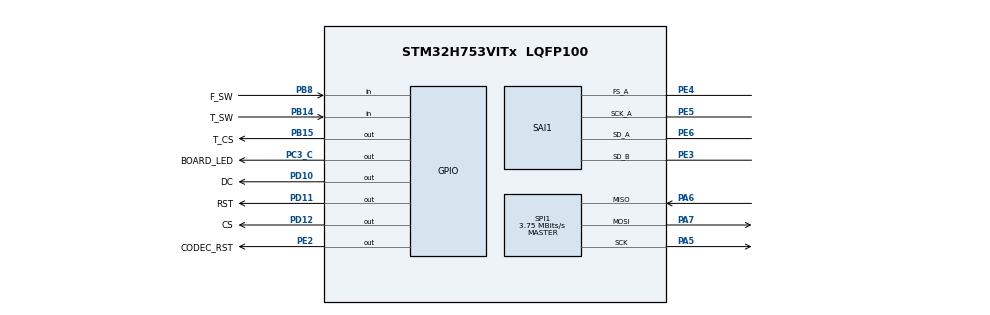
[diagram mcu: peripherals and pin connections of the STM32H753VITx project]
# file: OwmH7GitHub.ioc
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CORTEX_M7.CPU_DCache=Enabled
Mcu.Family=STM32H7
Mcu.Name=STM32H753VITx
Mcu.Package=LQFP100
NVIC.PriorityGroup=NVIC_PRIORITYGROUP_4
NVIC.SAI1_IRQn=true\:5\:0\:true\:false\:true\:true\:true
PA13\ (JTMS/SWDIO).Mode=Serial_Wire
PA13\ (JTMS/SWDIO).Signal=DEBUG_JTMS-SWDIO
PA14\ (JTCK/SWCLK).Mode=Serial_Wire
PA14\ (JTCK/SWCLK).Signal=DEBUG_JTCK-SWCLK
PA5.Mode=Full_Duplex_Master
PA5.Signal=SPI1_SCK
PA6.Mode=Full_Duplex_Master
PA6.Signal=SPI1_MISO
PA7.Mode=Full_Duplex_Master
PA7.Signal=SPI1_MOSI
PB14.GPIO_Label=T_SW
PB14.GPIO_Mode=GPIO_MODE_INPUT
PB14.GPIO_PuPd=GPIO_NOPULL
PB14.Signal=GPIO_Input
PB15.GPIO_Label=T_CS
PB15.GPIO_ModeDefaultOutputPP=GPIO_MODE_OUTPUT_PP
PB15.GPIO_PuPd=GPIO_NOPULL
PB15.GPIO_Speed=GPIO_SPEED_FREQ_LOW
PB15.PinState=GPIO_PIN_RESET
PB15.Signal=GPIO_Output
PB3\ (JTDO/TRACESWO).Signal=DEBUG_JTDO-SWO
PB8.GPIO_Label=F_SW
PB8.GPIO_Mode=GPIO_MODE_INPUT
PB8.GPIO_PuPd=GPIO_NOPULL
PB8.Signal=GPIO_Input
PC3_C.GPIO_Label=BOARD_LED
PC3_C.GPIO_ModeDefaultOutputPP=GPIO_MODE_OUTPUT_PP
PC3_C.GPIO_PuPd=GPIO_NOPULL
PC3_C.GPIO_Speed=GPIO_SPEED_FREQ_LOW
PC3_C.PinState=GPIO_PIN_RESET
PC3_C.Signal=GPIO_Output
PD10.GPIO_Label=DC
PD10.GPIO_ModeDefaultOutputPP=GPIO_MODE_OUTPUT_PP
PD10.GPIO_PuPd=GPIO_NOPULL
PD10.GPIO_Speed=GPIO_SPEED_FREQ_LOW
PD10.PinState=GPIO_PIN_RESET
PD10.Signal=GPIO_Output
PD11.GPIO_Label=RST
PD11.GPIO_ModeDefaultOutputPP=GPIO_MODE_OUTPUT_PP
PD11.GPIO_PuPd=GPIO_NOPULL
PD11.GPIO_Speed=GPIO_SPEED_FREQ_LOW
PD11.PinState=GPIO_PIN_RESET
PD11.Signal=GPIO_Output
PD12.GPIO_Label=CS
PD12.GPIO_ModeDefaultOutputPP=GPIO_MODE_OUTPUT_PP
PD12.GPIO_PuPd=GPIO_NOPULL
PD12.GPIO_Speed=GPIO_SPEED_FREQ_LOW
PD12.PinState=GPIO_PIN_RESET
PD12.Signal=GPIO_Output
PE2.GPIO_Label=CODEC_RST
PE2.GPIO_ModeDefaultOutputPP=GPIO_MODE_OUTPUT_PP
PE2.GPIO_PuPd=GPIO_NOPULL
PE2.GPIO_Speed=GPIO_SPEED_FREQ_LOW
PE2.PinState=GPIO_PIN_RESET
PE2.Signal=GPIO_Output
PE3.GPIO_Mode=GPIO_MODE_AF_PP
PE3.GPIO_PuPd=GPIO_NOPULL
PE3.GPIO_Speed=GPIO_SPEED_FREQ_LOW
PE3.Mode=SAI_B_SyncSlave
PE3.Signal=SAI1_SD_B
PE4.GPIO_Mode=GPIO_MODE_AF_PP
PE4.GPIO_PuPd=GPIO_NOPULL
PE4.GPIO_Speed=GPIO_SPEED_FREQ_LOW
PE4.Mode=SAI_A_AsyncSlave
PE4.Signal=SAI1_FS_A
PE5.GPIO_Mode=GPIO_MODE_AF_PP
PE5.GPIO_PuPd=GPIO_NOPULL
PE5.GPIO_Speed=GPIO_SPEED_FREQ_LOW
PE5.Mode=SAI_A_AsyncSlave
PE5.Signal=SAI1_SCK_A
PE6.GPIO_Mode=GPIO_MODE_AF_PP
PE6.GPIO_PuPd=GPIO_NOPULL
PE6.GPIO_Speed=GPIO_SPEED_FREQ_LOW
PE6.Mode=SAI_A_AsyncSlave
PE6.Signal=SAI1_SD_A
PH0-OSC_IN\ (PH0).Mode=HSE-External-Oscillator
PH0-OSC_IN\ (PH0).Signal=RCC_OSC_IN
PH1-OSC_OUT\ (PH1).Mode=HSE-External-Oscillator
PH1-OSC_OUT\ (PH1).Signal=RCC_OSC_OUT
ProjectManager.HeapSize=0x200
ProjectManager.StackSize=0x400
ProjectManager.TargetToolchain=STM32CubeIDE
RCC.ADCFreq_Value=90333333.33333333
RCC.APB1Freq_Value=120000000
RCC.APB2Freq_Value=120000000
RCC.APB3Freq_Value=120000000
RCC.APB4Freq_Value=120000000
RCC.CortexFreq_Value=480000000
RCC.D1PPRE=RCC_APB3_DIV2
RCC.D2PPRE1=RCC_APB1_DIV2
RCC.D2PPRE2=RCC_APB2_DIV2
RCC.D3PPRE=RCC_APB4_DIV2
RCC.DIVM1=4
RCC.DIVM2=8
RCC.DIVN1=480
RCC.DIVN2=271
RCC.DIVP2=3
RCC.HCLKFreq_Value=240000000
RCC.HPRE=RCC_HCLK_DIV2
RCC.HSE_VALUE=8000000
RCC.PLLSourceVirtual=RCC_PLLSOURCE_HSE
RCC.PWR_Regulator_Voltage_Scale=PWR_REGULATOR_VOLTAGE_SCALE0
RCC.SAI1CLockSelection=RCC_SAI1CLKSOURCE_PLL2
RCC.SYSCLKFreq_VALUE=480000000
RCC.SYSCLKSource=RCC_SYSCLKSOURCE_PLLCLK
RCC.USBFreq_Value=480000000
SAI1.AudioMode-SAI_B_SyncSlave=SAI_MODESLAVE_TX
SAI1.BasicDataSize-SAI_A_AsyncSlave=SAI_PROTOCOL_DATASIZE_32BIT
SAI1.BasicDataSize-SAI_B_SyncSlave=SAI_PROTOCOL_DATASIZE_32BIT
SAI1.FIFOThreshold-SAI_A_AsyncSlave=SAI_FIFOTHRESHOLD_HF
SAI1.FIFOThreshold-SAI_B_SyncSlave=SAI_FIFOTHRESHOLD_HF
SAI1.InitProtocol-SAI_A_AsyncSlave=Enable
SAI1.InitProtocol-SAI_B_SyncSlave=Enable
SAI1.Instance-SAI_A_AsyncSlave=SAI$Index_Block_A
SAI1.Instance-SAI_B_SyncSlave=SAI$Index_Block_B
SAI1.VirtualMode-SAI_A_AsyncSlave=VM_SLAVE
SAI1.VirtualMode-SAI_B_SyncSlave=VM_SLAVE
SAI1.VirtualProtocol-SAI_A_BASIC=VM_BASIC_PROTOCOL
SAI1.VirtualProtocol-SAI_B_BASIC=VM_BASIC_PROTOCOL
SPI1.BaudRatePrescaler=SPI_BAUDRATEPRESCALER_128
SPI1.CalculateBaudRate=3.75 MBits/s
SPI1.DataSize=SPI_DATASIZE_8BIT
SPI1.Direction=SPI_DIRECTION_2LINES
SPI1.Mode=SPI_MODE_MASTER
SPI1.VirtualType=VM_MASTER
VP_SAI1_VP_$IpInstance_SAIA_SAI_BASIC.Mode=SAI_A_BASIC
VP_SAI1_VP_$IpInstance_SAIB_SAI_BASIC.Mode=SAI_B_BASIC
board=custom

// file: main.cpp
/* USER CODE BEGIN Header */
/**
  ******************************************************************************
  * @file           : main.c
  * @brief          : Main program body
  ******************************************************************************
  * @attention
  *
  * <h2><center>&copy; Copyright (c) 2020 STMicroelectronics.
  * All rights reserved.</center></h2>
  *
  * This software component is licensed by ST under BSD 3-Clause license,
  * the "License"; You may not use this file except in compliance with the
  * License. You may obtain a copy of the License at:
  *                        opensource.org/licenses/BSD-3-Clause
  *
  ******************************************************************************
  */
/* USER CODE END Header */

#include "main.h"

/* USER CODE BEGIN Includes */
#include "user_main.hpp"

/* USER CODE END Includes */

SAI_HandleTypeDef hsai_BlockA1;
SAI_HandleTypeDef hsai_BlockB1;

SPI_HandleTypeDef hspi1;

void SystemClock_Config(void);
static void MX_GPIO_Init(void);
static void MX_SAI1_Init(void);
static void MX_SPI1_Init(void);

int main(void)
{

  /* Enable D-Cache---------------------------------------------------------*/
  SCB_EnableDCache();

  /* MCU Configuration--------------------------------------------------------*/

  /* Reset of all peripherals, Initializes the Flash interface and the Systick. */
  HAL_Init();

  /* Configure the system clock */
  SystemClock_Config();

  /* Initialize all configured peripherals */
  MX_GPIO_Init();
  MX_SAI1_Init();
  MX_SPI1_Init();
  /* USER CODE BEGIN 2 */
  mainInit();

  /* USER CODE END 2 */

  /* Infinite loop */
  while (1)
  {

    /* USER CODE BEGIN 3 */
    mainLoop();
  }
  /* USER CODE END 3 */
}

void SystemClock_Config(void)
{
  RCC_OscInitTypeDef RCC_OscInitStruct = {0};
  RCC_ClkInitTypeDef RCC_ClkInitStruct = {0};
  RCC_PeriphCLKInitTypeDef PeriphClkInitStruct = {0};

  /** Supply configuration update enable
  */
  HAL_PWREx_ConfigSupply(PWR_LDO_SUPPLY);
  /** Configure the main internal regulator output voltage
  */
  __HAL_PWR_VOLTAGESCALING_CONFIG(PWR_REGULATOR_VOLTAGE_SCALE0);

  while(!__HAL_PWR_GET_FLAG(PWR_FLAG_VOSRDY)) {}
  /** Macro to configure the PLL clock source
  */
  __HAL_RCC_PLL_PLLSOURCE_CONFIG(RCC_PLLSOURCE_HSE);
  /** Initializes the CPU, AHB and APB busses clocks
  */
  RCC_OscInitStruct.OscillatorType = RCC_OSCILLATORTYPE_HSE;
  RCC_OscInitStruct.HSEState = RCC_HSE_ON;
  RCC_OscInitStruct.PLL.PLLState = RCC_PLL_ON;
  RCC_OscInitStruct.PLL.PLLSource = RCC_PLLSOURCE_HSE;
  RCC_OscInitStruct.PLL.PLLM = 4;
  RCC_OscInitStruct.PLL.PLLN = 480;
  RCC_OscInitStruct.PLL.PLLP = 2;
  RCC_OscInitStruct.PLL.PLLQ = 2;
  RCC_OscInitStruct.PLL.PLLR = 2;
  RCC_OscInitStruct.PLL.PLLRGE = RCC_PLL1VCIRANGE_1;
  RCC_OscInitStruct.PLL.PLLVCOSEL = RCC_PLL1VCOWIDE;
  RCC_OscInitStruct.PLL.PLLFRACN = 0;
  if (HAL_RCC_OscConfig(&RCC_OscInitStruct) != HAL_OK)
  {
    Error_Handler();
  }
  /** Initializes the CPU, AHB and APB busses clocks
  */
  RCC_ClkInitStruct.ClockType = RCC_CLOCKTYPE_HCLK|RCC_CLOCKTYPE_SYSCLK
                              |RCC_CLOCKTYPE_PCLK1|RCC_CLOCKTYPE_PCLK2
                              |RCC_CLOCKTYPE_D3PCLK1|RCC_CLOCKTYPE_D1PCLK1;
  RCC_ClkInitStruct.SYSCLKSource = RCC_SYSCLKSOURCE_PLLCLK;
  RCC_ClkInitStruct.SYSCLKDivider = RCC_SYSCLK_DIV1;
  RCC_ClkInitStruct.AHBCLKDivider = RCC_HCLK_DIV2;
  RCC_ClkInitStruct.APB3CLKDivider = RCC_APB3_DIV2;
  RCC_ClkInitStruct.APB1CLKDivider = RCC_APB1_DIV2;
  RCC_ClkInitStruct.APB2CLKDivider = RCC_APB2_DIV2;
  RCC_ClkInitStruct.APB4CLKDivider = RCC_APB4_DIV2;

  if (HAL_RCC_ClockConfig(&RCC_ClkInitStruct, FLASH_LATENCY_4) != HAL_OK)
  {
    Error_Handler();
  }
  PeriphClkInitStruct.PeriphClockSelection = RCC_PERIPHCLK_SPI1|RCC_PERIPHCLK_SAI1;
  PeriphClkInitStruct.PLL2.PLL2M = 8;
  PeriphClkInitStruct.PLL2.PLL2N = 271;
  PeriphClkInitStruct.PLL2.PLL2P = 3;
  PeriphClkInitStruct.PLL2.PLL2Q = 2;
  PeriphClkInitStruct.PLL2.PLL2R = 2;
  PeriphClkInitStruct.PLL2.PLL2RGE = RCC_PLL2VCIRANGE_0;
  PeriphClkInitStruct.PLL2.PLL2VCOSEL = RCC_PLL2VCOWIDE;
  PeriphClkInitStruct.PLL2.PLL2FRACN = 0;
  PeriphClkInitStruct.Sai1ClockSelection = RCC_SAI1CLKSOURCE_PLL2;
  PeriphClkInitStruct.Spi123ClockSelection = RCC_SPI123CLKSOURCE_PLL;
  if (HAL_RCCEx_PeriphCLKConfig(&PeriphClkInitStruct) != HAL_OK)
  {
    Error_Handler();
  }
}

static void MX_SAI1_Init(void)
{

  hsai_BlockA1.Instance = SAI1_Block_A;
  hsai_BlockA1.Init.AudioMode = SAI_MODESLAVE_RX;
  hsai_BlockA1.Init.Synchro = SAI_ASYNCHRONOUS;
  hsai_BlockA1.Init.OutputDrive = SAI_OUTPUTDRIVE_DISABLE;
  hsai_BlockA1.Init.FIFOThreshold = SAI_FIFOTHRESHOLD_HF;
  hsai_BlockA1.Init.SynchroExt = SAI_SYNCEXT_DISABLE;
  hsai_BlockA1.Init.MonoStereoMode = SAI_STEREOMODE;
  hsai_BlockA1.Init.CompandingMode = SAI_NOCOMPANDING;
  hsai_BlockA1.Init.TriState = SAI_OUTPUT_NOTRELEASED;
  if (HAL_SAI_InitProtocol(&hsai_BlockA1, SAI_I2S_STANDARD, SAI_PROTOCOL_DATASIZE_32BIT, 2) != HAL_OK)
  {
    Error_Handler();
  }
  hsai_BlockB1.Instance = SAI1_Block_B;
  hsai_BlockB1.Init.AudioMode = SAI_MODESLAVE_TX;
  hsai_BlockB1.Init.Synchro = SAI_SYNCHRONOUS;
  hsai_BlockB1.Init.OutputDrive = SAI_OUTPUTDRIVE_DISABLE;
  hsai_BlockB1.Init.FIFOThreshold = SAI_FIFOTHRESHOLD_HF;
  hsai_BlockB1.Init.SynchroExt = SAI_SYNCEXT_DISABLE;
  hsai_BlockB1.Init.MonoStereoMode = SAI_STEREOMODE;
  hsai_BlockB1.Init.CompandingMode = SAI_NOCOMPANDING;
  hsai_BlockB1.Init.TriState = SAI_OUTPUT_NOTRELEASED;
  if (HAL_SAI_InitProtocol(&hsai_BlockB1, SAI_I2S_STANDARD, SAI_PROTOCOL_DATASIZE_32BIT, 2) != HAL_OK)
  {
    Error_Handler();
  }

}

static void MX_SPI1_Init(void)
{

  /* SPI1 parameter configuration*/
  hspi1.Instance = SPI1;
  hspi1.Init.Mode = SPI_MODE_MASTER;
  hspi1.Init.Direction = SPI_DIRECTION_2LINES;
  hspi1.Init.DataSize = SPI_DATASIZE_8BIT;
  hspi1.Init.CLKPolarity = SPI_POLARITY_LOW;
  hspi1.Init.CLKPhase = SPI_PHASE_1EDGE;
  hspi1.Init.NSS = SPI_NSS_SOFT;
  hspi1.Init.BaudRatePrescaler = SPI_BAUDRATEPRESCALER_128;
  hspi1.Init.FirstBit = SPI_FIRSTBIT_MSB;
  hspi1.Init.TIMode = SPI_TIMODE_DISABLE;
  hspi1.Init.CRCCalculation = SPI_CRCCALCULATION_DISABLE;
  hspi1.Init.CRCPolynomial = 0x0;
  hspi1.Init.NSSPMode = SPI_NSS_PULSE_ENABLE;
  hspi1.Init.NSSPolarity = SPI_NSS_POLARITY_LOW;
  hspi1.Init.FifoThreshold = SPI_FIFO_THRESHOLD_01DATA;
  hspi1.Init.TxCRCInitializationPattern = SPI_CRC_INITIALIZATION_ALL_ZERO_PATTERN;
  hspi1.Init.RxCRCInitializationPattern = SPI_CRC_INITIALIZATION_ALL_ZERO_PATTERN;
  hspi1.Init.MasterSSIdleness = SPI_MASTER_SS_IDLENESS_00CYCLE;
  hspi1.Init.MasterInterDataIdleness = SPI_MASTER_INTERDATA_IDLENESS_00CYCLE;
  hspi1.Init.MasterReceiverAutoSusp = SPI_MASTER_RX_AUTOSUSP_DISABLE;
  hspi1.Init.MasterKeepIOState = SPI_MASTER_KEEP_IO_STATE_DISABLE;
  hspi1.Init.IOSwap = SPI_IO_SWAP_DISABLE;
  if (HAL_SPI_Init(&hspi1) != HAL_OK)
  {
    Error_Handler();
  }

}

static void MX_GPIO_Init(void)
{
  GPIO_InitTypeDef GPIO_InitStruct = {0};

  /* GPIO Ports Clock Enable */
  __HAL_RCC_GPIOE_CLK_ENABLE();
  __HAL_RCC_GPIOH_CLK_ENABLE();
  __HAL_RCC_GPIOC_CLK_ENABLE();
  __HAL_RCC_GPIOA_CLK_ENABLE();
  __HAL_RCC_GPIOB_CLK_ENABLE();
  __HAL_RCC_GPIOD_CLK_ENABLE();

  /*Configure GPIO pin Output Level */
  HAL_GPIO_WritePin(CODEC_RST_GPIO_Port, CODEC_RST_Pin, GPIO_PIN_RESET);

  /*Configure GPIO pin Output Level */
  HAL_GPIO_WritePin(BOARD_LED_GPIO_Port, BOARD_LED_Pin, GPIO_PIN_RESET);

  /*Configure GPIO pin Output Level */
  HAL_GPIO_WritePin(T_CS_GPIO_Port, T_CS_Pin, GPIO_PIN_RESET);

  /*Configure GPIO pin Output Level */
  HAL_GPIO_WritePin(GPIOD, DC_Pin|RST_Pin|CS_Pin, GPIO_PIN_RESET);

  /*Configure GPIO pin : CODEC_RST_Pin */
  GPIO_InitStruct.Pin = CODEC_RST_Pin;
  GPIO_InitStruct.Mode = GPIO_MODE_OUTPUT_PP;
  GPIO_InitStruct.Pull = GPIO_NOPULL;
  GPIO_InitStruct.Speed = GPIO_SPEED_FREQ_LOW;
  HAL_GPIO_Init(CODEC_RST_GPIO_Port, &GPIO_InitStruct);

  /*Configure GPIO pin : BOARD_LED_Pin */
  GPIO_InitStruct.Pin = BOARD_LED_Pin;
  GPIO_InitStruct.Mode = GPIO_MODE_OUTPUT_PP;
  GPIO_InitStruct.Pull = GPIO_NOPULL;
  GPIO_InitStruct.Speed = GPIO_SPEED_FREQ_LOW;
  HAL_GPIO_Init(BOARD_LED_GPIO_Port, &GPIO_InitStruct);

  /*Configure GPIO pins : T_SW_Pin F_SW_Pin */
  GPIO_InitStruct.Pin = T_SW_Pin|F_SW_Pin;
  GPIO_InitStruct.Mode = GPIO_MODE_INPUT;
  GPIO_InitStruct.Pull = GPIO_NOPULL;
  HAL_GPIO_Init(GPIOB, &GPIO_InitStruct);

  /*Configure GPIO pin : T_CS_Pin */
  GPIO_InitStruct.Pin = T_CS_Pin;
  GPIO_InitStruct.Mode = GPIO_MODE_OUTPUT_PP;
  GPIO_InitStruct.Pull = GPIO_NOPULL;
  GPIO_InitStruct.Speed = GPIO_SPEED_FREQ_LOW;
  HAL_GPIO_Init(T_CS_GPIO_Port, &GPIO_InitStruct);

  /*Configure GPIO pins : DC_Pin RST_Pin CS_Pin */
  GPIO_InitStruct.Pin = DC_Pin|RST_Pin|CS_Pin;
  GPIO_InitStruct.Mode = GPIO_MODE_OUTPUT_PP;
  GPIO_InitStruct.Pull = GPIO_NOPULL;
  GPIO_InitStruct.Speed = GPIO_SPEED_FREQ_LOW;
  HAL_GPIO_Init(GPIOD, &GPIO_InitStruct);

}

void Error_Handler(void)
{
}

/************************ (C) COPYRIGHT STMicroelectronics *****END OF FILE****/
